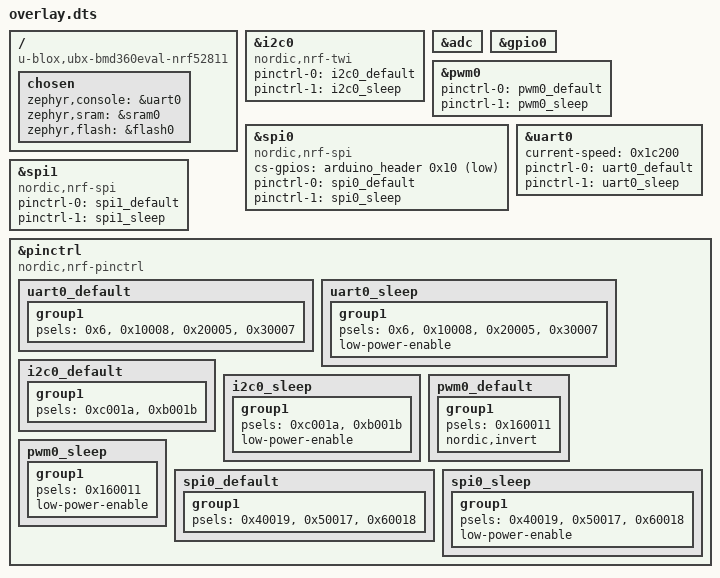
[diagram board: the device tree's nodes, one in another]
/ {
	compatible = "u-blox,ubx-bmd360eval-nrf52811";
	chosen {
		zephyr,console = &uart0;
		zephyr,sram = &sram0;
		zephyr,flash = &flash0;
	};
};
&i2c0{
	compatible = "nordic,nrf-twi";
	status = "okay";
	pinctrl-0 = < &i2c0_default >;
	pinctrl-1 = < &i2c0_sleep >;
	pinctrl-names = "default", "sleep";
};
&adc{
	status = "okay";
};
&gpio0{
	status = "okay";
};
&pwm0{
	status = "okay";
	pinctrl-0 = < &pwm0_default >;
	pinctrl-1 = < &pwm0_sleep >;
	pinctrl-names = "default", "sleep";
};
&spi0{
	compatible = "nordic,nrf-spi";
	status = "okay";
	cs-gpios = < &arduino_header 0x10 0x1 >;
	pinctrl-0 = < &spi0_default >;
	pinctrl-1 = < &spi0_sleep >;
	pinctrl-names = "default", "sleep";
};
&uart0{
	status = "okay";
	current-speed = < 0x1c200 >;
	pinctrl-0 = < &uart0_default >;
	pinctrl-1 = < &uart0_sleep >;
	pinctrl-names = "default", "sleep";
};
&spi1{
	compatible = "nordic,nrf-spi";
	pinctrl-0 = < &spi1_default >;
	pinctrl-1 = < &spi1_sleep >;
	pinctrl-names = "default", "sleep";
};
&pinctrl{
	compatible = "nordic,nrf-pinctrl";
	uart0_default: uart0_default {
		group1 {
			psels = < 0x6 >, < 0x10008 >, < 0x20005 >, < 0x30007 >;
		};
	};
	uart0_sleep: uart0_sleep {
		group1 {
			psels = < 0x6 >, < 0x10008 >, < 0x20005 >, < 0x30007 >;
			low-power-enable;
		};
	};
	i2c0_default: i2c0_default {
		group1 {
			psels = < 0xc001a >, < 0xb001b >;
		};
	};
	i2c0_sleep: i2c0_sleep {
		group1 {
			psels = < 0xc001a >, < 0xb001b >;
			low-power-enable;
		};
	};
	pwm0_default: pwm0_default {
		group1 {
			psels = < 0x160011 >;
			nordic,invert;
		};
	};
	pwm0_sleep: pwm0_sleep {
		group1 {
			psels = < 0x160011 >;
			low-power-enable;
		};
	};
	spi0_default: spi0_default {
		group1 {
			psels = < 0x40019 >, < 0x50017 >, < 0x60018 >;
		};
	};
	spi0_sleep: spi0_sleep {
		group1 {
			psels = < 0x40019 >, < 0x50017 >, < 0x60018 >;
			low-power-enable;
		};
	};
};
